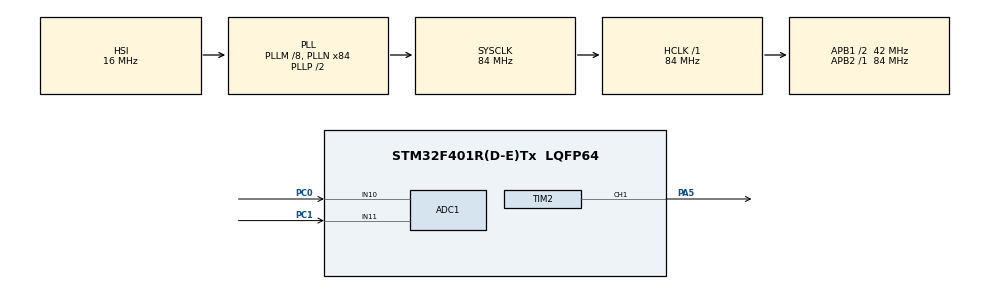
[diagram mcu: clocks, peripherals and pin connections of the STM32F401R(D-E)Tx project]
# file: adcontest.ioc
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ADC1.Channel-18\#ChannelRegularConversion=ADC_CHANNEL_10
ADC1.DMAContinuousRequests=ENABLE
ADC1.NbrOfConversionFlag=1
ADC1.Rank-18\#ChannelRegularConversion=1
ADC1.SamplingTime-18\#ChannelRegularConversion=ADC_SAMPLETIME_3CYCLES
ADC1.master=1
Dma.ADC1.0.Direction=DMA_PERIPH_TO_MEMORY
Dma.ADC1.0.FIFOMode=DMA_FIFOMODE_DISABLE
Dma.ADC1.0.Instance=DMA2_Stream0
Dma.ADC1.0.MemDataAlignment=DMA_MDATAALIGN_HALFWORD
Dma.ADC1.0.MemInc=DMA_MINC_ENABLE
Dma.ADC1.0.Mode=DMA_NORMAL
Dma.ADC1.0.PeriphDataAlignment=DMA_PDATAALIGN_HALFWORD
Dma.ADC1.0.PeriphInc=DMA_PINC_DISABLE
Dma.ADC1.0.Priority=DMA_PRIORITY_LOW
Dma.Request0=ADC1
Mcu.Family=STM32F4
Mcu.Name=STM32F401R(D-E)Tx
Mcu.Package=LQFP64
NVIC.DMA2_Stream0_IRQn=true\:0\:0\:false\:false\:true
NVIC.PriorityGroup=NVIC_PRIORITYGROUP_4
PA5.GPIO_ModeDefaultPP=GPIO_MODE_AF_PP
PA5.GPIO_PuPd=GPIO_NOPULL
PA5.Signal=S_TIM2_CH1_ETR
PC0.Signal=ADCx_IN10
PC1.Signal=ADCx_IN11
ProjectManager.HeapSize=0x200
ProjectManager.StackSize=0x400
ProjectManager.TargetToolchain=SW4STM32
RCC.48MHZClocksFreq_Value=42000000
RCC.AHBFreq_Value=84000000
RCC.APB1CLKDivider=RCC_HCLK_DIV2
RCC.APB1Freq_Value=42000000
RCC.APB1TimFreq_Value=84000000
RCC.APB2Freq_Value=84000000
RCC.APB2TimFreq_Value=84000000
RCC.CortexFreq_Value=84000000
RCC.HCLKFreq_Value=84000000
RCC.HSE_VALUE=25000000
RCC.HSI_VALUE=16000000
RCC.LSE_VALUE=32768
RCC.PLLM=8
RCC.PLLN=84
RCC.SYSCLKFreq_VALUE=84000000
RCC.SYSCLKSource=RCC_SYSCLKSOURCE_PLLCLK
RCC.VCOOutputFreq_Value=168000000
SH.ADCx_IN10.0=ADC1_IN10,IN10
SH.ADCx_IN11.0=ADC1_IN11,IN11
SH.S_TIM2_CH1_ETR.0=TIM2_CH1,PWM Generation1 CH1
TIM2.Channel-PWM\ Generation1\ CH1=TIM_CHANNEL_1
TIM2.Period=4095
TIM2.Pulse-PWM\ Generation1\ CH1=0
VP_TIM2_VS_ClockSourceINT.Mode=Internal
board=adcontest

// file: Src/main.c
/**
  ******************************************************************************
  * File Name          : main.c
  * Description        : Main program body
  ******************************************************************************
  ** This notice applies to any and all portions of this file
  * that are not between comment pairs USER CODE BEGIN and
  * USER CODE END. Other portions of this file, whether
  * inserted by the user or by software development tools
  * are owned by their respective copyright owners.
  *
  * COPYRIGHT(c) 2017 STMicroelectronics
  *
  * Redistribution and use in source and binary forms, with or without modification,
  * are permitted provided that the following conditions are met:
  *   1. Redistributions of source code must retain the above copyright notice,
  *      this list of conditions and the following disclaimer.
  *   2. Redistributions in binary form must reproduce the above copyright notice,
  *      this list of conditions and the following disclaimer in the documentation
  *      and/or other materials provided with the distribution.
  *   3. Neither the name of STMicroelectronics nor the names of its contributors
  *      may be used to endorse or promote products derived from this software
  *      without specific prior written permission.
  *
  * THIS SOFTWARE IS PROVIDED BY THE COPYRIGHT HOLDERS AND CONTRIBUTORS "AS IS"
  * AND ANY EXPRESS OR IMPLIED WARRANTIES, INCLUDING, BUT NOT LIMITED TO, THE
  * IMPLIED WARRANTIES OF MERCHANTABILITY AND FITNESS FOR A PARTICULAR PURPOSE ARE
  * DISCLAIMED. IN NO EVENT SHALL THE COPYRIGHT HOLDER OR CONTRIBUTORS BE LIABLE
  * FOR ANY DIRECT, INDIRECT, INCIDENTAL, SPECIAL, EXEMPLARY, OR CONSEQUENTIAL
  * DAMAGES (INCLUDING, BUT NOT LIMITED TO, PROCUREMENT OF SUBSTITUTE GOODS OR
  * SERVICES; LOSS OF USE, DATA, OR PROFITS; OR BUSINESS INTERRUPTION) HOWEVER
  * CAUSED AND ON ANY THEORY OF LIABILITY, WHETHER IN CONTRACT, STRICT LIABILITY,
  * OR TORT (INCLUDING NEGLIGENCE OR OTHERWISE) ARISING IN ANY WAY OUT OF THE USE
  * OF THIS SOFTWARE, EVEN IF ADVISED OF THE POSSIBILITY OF SUCH DAMAGE.
  *
  ******************************************************************************
  */
#include "main.h"
#include "stm32f4xx_hal.h"

ADC_HandleTypeDef hadc1;
DMA_HandleTypeDef hdma_adc1;

TIM_HandleTypeDef htim2;

/* USER CODE BEGIN PV */
/* Private variables ---------------------------------------------------------*/
static uint16_t adc_data[2];
/* USER CODE END PV */

void SystemClock_Config(void);
static void MX_GPIO_Init(void);
static void MX_DMA_Init(void);
static void MX_TIM2_Init(void);
static void MX_ADC1_Init(void);

void HAL_TIM_MspPostInit(TIM_HandleTypeDef *htim);

/* USER CODE BEGIN PFP */
/* Private function prototypes -----------------------------------------------*/

/* USER CODE END PFP */

int main(void)
{

  /* MCU Configuration----------------------------------------------------------*/

  /* Reset of all peripherals, Initializes the Flash interface and the Systick. */
  HAL_Init();

  /* Configure the system clock */
  SystemClock_Config();

  /* Initialize all configured peripherals */
  MX_GPIO_Init();
  MX_DMA_Init();
  MX_TIM2_Init();
  MX_ADC1_Init();

  /* USER CODE BEGIN 2 */
  volatile unsigned int *tim2_ccr1 = (unsigned int*)0x40000034;
  int accel, current;
  HAL_TIM_PWM_Start(&htim2, TIM_CHANNEL_1);

  /* USER CODE END 2 */

  /* Infinite loop */
  /* USER CODE BEGIN WHILE */
  while (1)
  {
	  if(HAL_ADC_Start_DMA(&hadc1, (uint32_t*)adc_data, 2) != HAL_OK) {
		  HAL_Delay(500);
		  HAL_ADC_Stop_DMA(&hadc1);
	  }
		accel = adc_data[0];
		current = adc_data[1];
		*tim2_ccr1 = accel;
  /* USER CODE END WHILE */

  }

}

/** System Clock Configuration
*/
void SystemClock_Config(void)
{

  RCC_OscInitTypeDef RCC_OscInitStruct;
  RCC_ClkInitTypeDef RCC_ClkInitStruct;

    /**Configure the main internal regulator output voltage
    */
  __HAL_RCC_PWR_CLK_ENABLE();

  __HAL_PWR_VOLTAGESCALING_CONFIG(PWR_REGULATOR_VOLTAGE_SCALE2);

    /**Initializes the CPU, AHB and APB busses clocks
    */
  RCC_OscInitStruct.OscillatorType = RCC_OSCILLATORTYPE_HSI;
  RCC_OscInitStruct.HSIState = RCC_HSI_ON;
  RCC_OscInitStruct.HSICalibrationValue = 16;
  RCC_OscInitStruct.PLL.PLLState = RCC_PLL_ON;
  RCC_OscInitStruct.PLL.PLLSource = RCC_PLLSOURCE_HSI;
  RCC_OscInitStruct.PLL.PLLM = 8;
  RCC_OscInitStruct.PLL.PLLN = 84;
  RCC_OscInitStruct.PLL.PLLP = RCC_PLLP_DIV2;
  RCC_OscInitStruct.PLL.PLLQ = 4;
  if (HAL_RCC_OscConfig(&RCC_OscInitStruct) != HAL_OK)
  {
    _Error_Handler(__FILE__, __LINE__);
  }

    /**Initializes the CPU, AHB and APB busses clocks
    */
  RCC_ClkInitStruct.ClockType = RCC_CLOCKTYPE_HCLK|RCC_CLOCKTYPE_SYSCLK
                              |RCC_CLOCKTYPE_PCLK1|RCC_CLOCKTYPE_PCLK2;
  RCC_ClkInitStruct.SYSCLKSource = RCC_SYSCLKSOURCE_PLLCLK;
  RCC_ClkInitStruct.AHBCLKDivider = RCC_SYSCLK_DIV1;
  RCC_ClkInitStruct.APB1CLKDivider = RCC_HCLK_DIV2;
  RCC_ClkInitStruct.APB2CLKDivider = RCC_HCLK_DIV1;

  if (HAL_RCC_ClockConfig(&RCC_ClkInitStruct, FLASH_LATENCY_2) != HAL_OK)
  {
    _Error_Handler(__FILE__, __LINE__);
  }

    /**Configure the Systick interrupt time
    */
  HAL_SYSTICK_Config(HAL_RCC_GetHCLKFreq()/1000);

    /**Configure the Systick
    */
  HAL_SYSTICK_CLKSourceConfig(SYSTICK_CLKSOURCE_HCLK);

  /* SysTick_IRQn interrupt configuration */
  HAL_NVIC_SetPriority(SysTick_IRQn, 0, 0);
}

/* ADC1 init function */
static void MX_ADC1_Init(void)
{

  ADC_ChannelConfTypeDef sConfig;

    /**Configure the global features of the ADC (Clock, Resolution, Data Alignment and number of conversion)
    */
  hadc1.Instance = ADC1;
  hadc1.Init.ClockPrescaler = ADC_CLOCK_SYNC_PCLK_DIV4;
  hadc1.Init.Resolution = ADC_RESOLUTION_12B;
  hadc1.Init.ScanConvMode = DISABLE;
  hadc1.Init.ContinuousConvMode = DISABLE;
  hadc1.Init.DiscontinuousConvMode = DISABLE;
  hadc1.Init.ExternalTrigConvEdge = ADC_EXTERNALTRIGCONVEDGE_NONE;
  hadc1.Init.ExternalTrigConv = ADC_SOFTWARE_START;
  hadc1.Init.DataAlign = ADC_DATAALIGN_RIGHT;
  hadc1.Init.NbrOfConversion = 1;
  hadc1.Init.DMAContinuousRequests = ENABLE;
  hadc1.Init.EOCSelection = ADC_EOC_SINGLE_CONV;
  if (HAL_ADC_Init(&hadc1) != HAL_OK)
  {
    _Error_Handler(__FILE__, __LINE__);
  }

    /**Configure for the selected ADC regular channel its corresponding rank in the sequencer and its sample time.
    */
  sConfig.Channel = ADC_CHANNEL_10;
  sConfig.Rank = 1;
  sConfig.SamplingTime = ADC_SAMPLETIME_3CYCLES;
  if (HAL_ADC_ConfigChannel(&hadc1, &sConfig) != HAL_OK)
  {
    _Error_Handler(__FILE__, __LINE__);
  }

  sConfig.Channel = ADC_CHANNEL_11;
  sConfig.Rank = 2;
  if (HAL_ADC_ConfigChannel(&hadc1, &sConfig) != HAL_OK)
  {
    _Error_Handler(__FILE__, __LINE__);
  }

}

/* TIM2 init function */
static void MX_TIM2_Init(void)
{

  TIM_ClockConfigTypeDef sClockSourceConfig;
  TIM_MasterConfigTypeDef sMasterConfig;
  TIM_OC_InitTypeDef sConfigOC;

  htim2.Instance = TIM2;
  htim2.Init.Prescaler = 0;
  htim2.Init.CounterMode = TIM_COUNTERMODE_UP;
  htim2.Init.Period = 4095;
  htim2.Init.ClockDivision = TIM_CLOCKDIVISION_DIV1;
  if (HAL_TIM_Base_Init(&htim2) != HAL_OK)
  {
    _Error_Handler(__FILE__, __LINE__);
  }

  sClockSourceConfig.ClockSource = TIM_CLOCKSOURCE_INTERNAL;
  if (HAL_TIM_ConfigClockSource(&htim2, &sClockSourceConfig) != HAL_OK)
  {
    _Error_Handler(__FILE__, __LINE__);
  }

  if (HAL_TIM_PWM_Init(&htim2) != HAL_OK)
  {
    _Error_Handler(__FILE__, __LINE__);
  }

  sMasterConfig.MasterOutputTrigger = TIM_TRGO_RESET;
  sMasterConfig.MasterSlaveMode = TIM_MASTERSLAVEMODE_DISABLE;
  if (HAL_TIMEx_MasterConfigSynchronization(&htim2, &sMasterConfig) != HAL_OK)
  {
    _Error_Handler(__FILE__, __LINE__);
  }

  sConfigOC.OCMode = TIM_OCMODE_PWM1;
  sConfigOC.Pulse = 0;
  sConfigOC.OCPolarity = TIM_OCPOLARITY_HIGH;
  sConfigOC.OCFastMode = TIM_OCFAST_DISABLE;
  if (HAL_TIM_PWM_ConfigChannel(&htim2, &sConfigOC, TIM_CHANNEL_1) != HAL_OK)
  {
    _Error_Handler(__FILE__, __LINE__);
  }

  HAL_TIM_MspPostInit(&htim2);

}

static void MX_DMA_Init(void)
{
  /* DMA controller clock enable */
  __HAL_RCC_DMA2_CLK_ENABLE();

  /* DMA interrupt init */
  /* DMA2_Stream0_IRQn interrupt configuration */
  HAL_NVIC_SetPriority(DMA2_Stream0_IRQn, 0, 0);
  HAL_NVIC_EnableIRQ(DMA2_Stream0_IRQn);

}

/** Pinout Configuration
*/
static void MX_GPIO_Init(void)
{

  /* GPIO Ports Clock Enable */
  __HAL_RCC_GPIOC_CLK_ENABLE();
  __HAL_RCC_GPIOA_CLK_ENABLE();

}

void _Error_Handler(char * file, int line)
{
  while(1)
  {
  }
}

/************************ (C) COPYRIGHT STMicroelectronics *****END OF FILE****/
